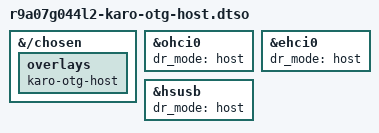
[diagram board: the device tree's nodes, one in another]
// SPDX-License-Identifier: (GPL-2.0 OR BSD-3-Clause)
/*
 * Copyright (C) 2023 Markus Bauer <MB@karo-electronics.com>
 */
/dts-v1/;
/plugin/;

&{/chosen} {
	overlays {
		karo-otg-host;
	};
};

&ohci0 {
	dr_mode = "host";
};

&ehci0 {
	dr_mode = "host";
};

&hsusb {
	dr_mode = "host";
};
